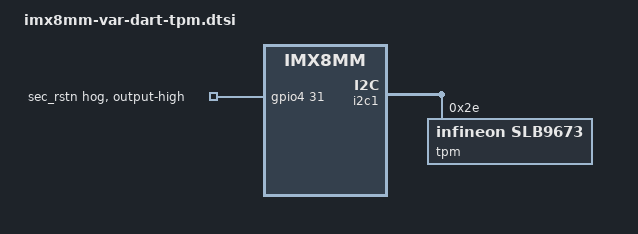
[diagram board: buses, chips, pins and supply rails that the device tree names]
// SPDX-License-Identifier: GPL-2.0+
/*
 * Copyright 2026 Variscite Ltd.
 */

&gpio4 {
	pinctrl-names = "default";
	pinctrl-0 = <&pinctrl_tpm_reset>;

	sec_rstn {
		gpio-hog;
		gpios = <31 GPIO_ACTIVE_HIGH>;
		output-high;
		line-name = "sec_rstn";
	};
};

&i2c1 {
	tpm@2e {
		compatible = "infineon,slb9673", "tcg,tpm-tis-i2c";
		reg = <0x2e>;
		status = "okay";
	};
};

&iomuxc {
	pinctrl_tpm_reset: tpm-resetgrp {
		fsl,pins = <
			MX8MM_IOMUXC_SAI3_TXFS_GPIO4_IO31		0x19
		>;
	};
};
